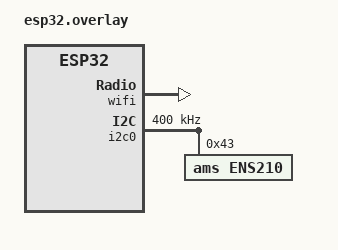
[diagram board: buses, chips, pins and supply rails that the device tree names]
/ {
    aliases {
        temperature = &ens210;
        humidity = &ens210;
    };
};

&wifi {
    status = "okay";
};

&i2c0 {
	status = "okay";
	clock-frequency = <I2C_BITRATE_FAST>;

	ens210: ens210@43 {
		compatible = "ams,ens210";
		reg = <0x43>;
	};
};
